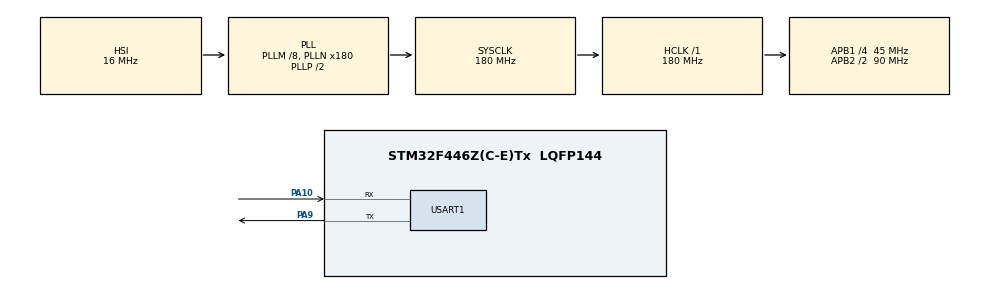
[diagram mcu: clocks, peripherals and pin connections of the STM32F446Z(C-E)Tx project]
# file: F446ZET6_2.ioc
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FREERTOS.BinarySemaphores01=BinSem,Dynamic,NULL
FREERTOS.INCLUDE_vTaskDelayUntil=1
FREERTOS.Tasks01=Task1,0,128,StartTask1,Default,NULL,Dynamic,NULL,NULL;Task2,2,128,StartTask2,Default,NULL,Dynamic,NULL,NULL;Task3,-2,128,StartTask3,Default,NULL,Dynamic,NULL,NULL
Mcu.Family=STM32F4
Mcu.Name=STM32F446Z(C-E)Tx
Mcu.Package=LQFP144
NVIC.PriorityGroup=NVIC_PRIORITYGROUP_4
NVIC.TIM1_UP_TIM10_IRQn=true\:15\:0\:false\:false\:true\:false\:false\:true\:true
NVIC.TimeBase=TIM1_UP_TIM10_IRQn
NVIC.TimeBaseIP=TIM1
PA10.Mode=Asynchronous
PA10.Signal=USART1_RX
PA13.Mode=Serial_Wire
PA13.Signal=SYS_JTMS-SWDIO
PA14.Mode=Serial_Wire
PA14.Signal=SYS_JTCK-SWCLK
PA9.Mode=Asynchronous
PA9.Signal=USART1_TX
ProjectManager.HeapSize=0x200
ProjectManager.StackSize=0x400
ProjectManager.TargetToolchain=STM32CubeIDE
RCC.AHBFreq_Value=180000000
RCC.APB1CLKDivider=RCC_HCLK_DIV4
RCC.APB1Freq_Value=45000000
RCC.APB1TimFreq_Value=90000000
RCC.APB2CLKDivider=RCC_HCLK_DIV2
RCC.APB2Freq_Value=90000000
RCC.APB2TimFreq_Value=180000000
RCC.CortexFreq_Value=180000000
RCC.HCLKFreq_Value=180000000
RCC.PLLM=8
RCC.PLLN=180
RCC.SYSCLKFreq_VALUE=180000000
RCC.SYSCLKSource=RCC_SYSCLKSOURCE_PLLCLK
RCC.USBFreq_Value=180000000
RCC.VCOOutputFreq_Value=360000000
USART1.VirtualMode=VM_ASYNC
VP_FREERTOS_VS_CMSIS_V1.Mode=CMSIS_V1
VP_SYS_VS_tim1.Mode=TIM1
board=custom

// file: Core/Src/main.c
/* USER CODE BEGIN Header */
/**
  ******************************************************************************
  * @file           : main.c
  * @brief          : Main program body
  ******************************************************************************
  * @attention
  *
  * Copyright (c) 2023 STMicroelectronics.
  * All rights reserved.
  *
  * This software is licensed under terms that can be found in the LICENSE file
  * in the root directory of this software component.
  * If no LICENSE file comes with this software, it is provided AS-IS.
  *
  ******************************************************************************
  */
/* USER CODE END Header */
#include "main.h"
#include "cmsis_os.h"

/* USER CODE BEGIN Includes */
#include <stdio.h>
/* USER CODE END Includes */

UART_HandleTypeDef huart1;

osThreadId Task1Handle;
osThreadId Task2Handle;
osThreadId Task3Handle;
osSemaphoreId BinSemHandle;
/* USER CODE BEGIN PV */
int indx = 0;
/* USER CODE END PV */

void SystemClock_Config(void);
static void MX_GPIO_Init(void);
static void MX_USART1_UART_Init(void);
void StartTask1(void const * argument);
void StartTask2(void const * argument);
void StartTask3(void const * argument);

/* USER CODE BEGIN PFP */
#ifdef __GNUC__
#define PUTCHAR_PROTOTYPE int __io_putchar(int ch)
#else
#define PUTCHAR_PROTOTYPE int fputc(int ch, FILE *f)
#endif

PUTCHAR_PROTOTYPE
{
  HAL_UART_Transmit(&huart1, (uint8_t *)&ch, 1, HAL_MAX_DELAY);
  return ch;
}
/* USER CODE END PFP */

int main(void)
{

  /* MCU Configuration--------------------------------------------------------*/

  /* Reset of all peripherals, Initializes the Flash interface and the Systick. */
  HAL_Init();

  /* Configure the system clock */
  SystemClock_Config();

  /* Initialize all configured peripherals */
  MX_GPIO_Init();
  MX_USART1_UART_Init();
  /* USER CODE BEGIN 2 */
  printf("Starting\n\r");
  /* USER CODE END 2 */

  /* Create the semaphores(s) */
  /* definition and creation of BinSem */
  osSemaphoreDef(BinSem);
  BinSemHandle = osSemaphoreCreate(osSemaphore(BinSem), 1);

  /* Create the thread(s) */
  /* definition and creation of Task1 */
  osThreadDef(Task1, StartTask1, osPriorityNormal, 0, 128);
  Task1Handle = osThreadCreate(osThread(Task1), NULL);

  /* definition and creation of Task2 */
  osThreadDef(Task2, StartTask2, osPriorityHigh, 0, 128);
  Task2Handle = osThreadCreate(osThread(Task2), NULL);

  /* definition and creation of Task3 */
  osThreadDef(Task3, StartTask3, osPriorityLow, 0, 128);
  Task3Handle = osThreadCreate(osThread(Task3), NULL);

  /* Start scheduler */
  osKernelStart();

  /* We should never get here as control is now taken by the scheduler */
  /* Infinite loop */
  while (1)
  {

  }
}

void SystemClock_Config(void)
{
  RCC_OscInitTypeDef RCC_OscInitStruct = {0};
  RCC_ClkInitTypeDef RCC_ClkInitStruct = {0};

  /** Configure the main internal regulator output voltage
  */
  __HAL_RCC_PWR_CLK_ENABLE();
  __HAL_PWR_VOLTAGESCALING_CONFIG(PWR_REGULATOR_VOLTAGE_SCALE1);

  /** Initializes the RCC Oscillators according to the specified parameters
  * in the RCC_OscInitTypeDef structure.
  */
  RCC_OscInitStruct.OscillatorType = RCC_OSCILLATORTYPE_HSI;
  RCC_OscInitStruct.HSIState = RCC_HSI_ON;
  RCC_OscInitStruct.HSICalibrationValue = RCC_HSICALIBRATION_DEFAULT;
  RCC_OscInitStruct.PLL.PLLState = RCC_PLL_ON;
  RCC_OscInitStruct.PLL.PLLSource = RCC_PLLSOURCE_HSI;
  RCC_OscInitStruct.PLL.PLLM = 8;
  RCC_OscInitStruct.PLL.PLLN = 180;
  RCC_OscInitStruct.PLL.PLLP = RCC_PLLP_DIV2;
  RCC_OscInitStruct.PLL.PLLQ = 2;
  RCC_OscInitStruct.PLL.PLLR = 2;
  if (HAL_RCC_OscConfig(&RCC_OscInitStruct) != HAL_OK)
  {
    Error_Handler();
  }

  /** Activate the Over-Drive mode
  */
  if (HAL_PWREx_EnableOverDrive() != HAL_OK)
  {
    Error_Handler();
  }

  /** Initializes the CPU, AHB and APB buses clocks
  */
  RCC_ClkInitStruct.ClockType = RCC_CLOCKTYPE_HCLK|RCC_CLOCKTYPE_SYSCLK
                              |RCC_CLOCKTYPE_PCLK1|RCC_CLOCKTYPE_PCLK2;
  RCC_ClkInitStruct.SYSCLKSource = RCC_SYSCLKSOURCE_PLLCLK;
  RCC_ClkInitStruct.AHBCLKDivider = RCC_SYSCLK_DIV1;
  RCC_ClkInitStruct.APB1CLKDivider = RCC_HCLK_DIV4;
  RCC_ClkInitStruct.APB2CLKDivider = RCC_HCLK_DIV2;

  if (HAL_RCC_ClockConfig(&RCC_ClkInitStruct, FLASH_LATENCY_5) != HAL_OK)
  {
    Error_Handler();
  }
}

static void MX_USART1_UART_Init(void)
{

  huart1.Instance = USART1;
  huart1.Init.BaudRate = 115200;
  huart1.Init.WordLength = UART_WORDLENGTH_8B;
  huart1.Init.StopBits = UART_STOPBITS_1;
  huart1.Init.Parity = UART_PARITY_NONE;
  huart1.Init.Mode = UART_MODE_TX_RX;
  huart1.Init.HwFlowCtl = UART_HWCONTROL_NONE;
  huart1.Init.OverSampling = UART_OVERSAMPLING_16;
  if (HAL_UART_Init(&huart1) != HAL_OK)
  {
    Error_Handler();
  }

}

static void MX_GPIO_Init(void)
{

  /* GPIO Ports Clock Enable */
  __HAL_RCC_GPIOA_CLK_ENABLE();

}

void StartTask1(void const * argument)
{
  /* USER CODE BEGIN 5 */
  /* Infinite loop */
  for(;;)
  {
	  printf("Enter Task 1\n\r");
	  printf("Leave Task 1\n\n\r");
	  osDelay(500);
  }
  /* USER CODE END 5 */
}

void StartTask2(void const * argument)
{
  /* USER CODE BEGIN StartTask2 */
  /* Infinite loop */
  for(;;)
  {
	  printf("Entered Task 2 and waiting for Semaphore\n\r");

	  osSemaphoreWait(BinSemHandle, osWaitForever);
	  printf("Semaphore Acquired by Task 2\n\r");

	  printf("Leaving Task 2 and releasing Semaphore\n\n\r");
	  osSemaphoreRelease(BinSemHandle);
	  osDelay(500);
  }
  /* USER CODE END StartTask2 */
}

void StartTask3(void const * argument)
{
  /* USER CODE BEGIN StartTask3 */
  /* Infinite loop */
  for(;;)
  {
	  printf("Entered Task 3 and waiting for Semaphore\n\r");

	  	  osSemaphoreWait(BinSemHandle, osWaitForever);
	  	  printf("Semaphore Acquired by Task 3\n\r");

	  	  printf("Leaving Task 3 and releasing Semaphore\n\n\r");
	  	  osSemaphoreRelease(BinSemHandle);
	  	  osDelay(500);
  }
  /* USER CODE END StartTask3 */
}

void HAL_TIM_PeriodElapsedCallback(TIM_HandleTypeDef *htim)
{
  if (htim->Instance == TIM1) {
    HAL_IncTick();
  }
}

void Error_Handler(void)
{
  __disable_irq();
  while (1)
  {
  }
}
